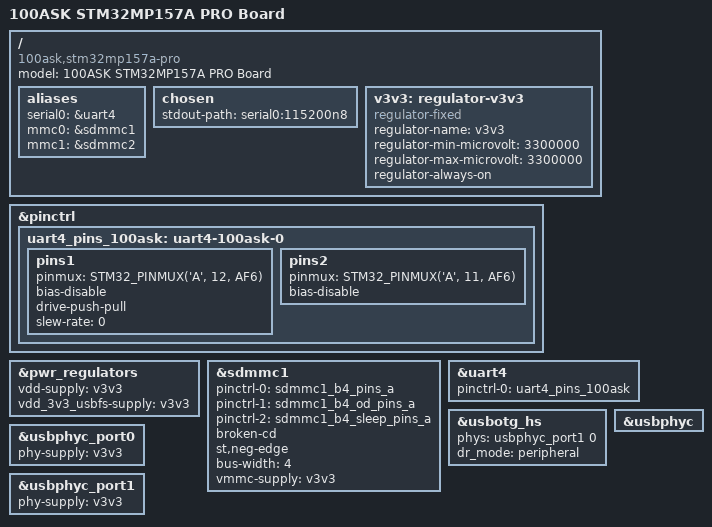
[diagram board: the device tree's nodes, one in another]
// SPDX-License-Identifier: (GPL-2.0+ OR BSD-3-Clause)
/*
 * 100ASK STM32MP157 PRO carrier board with a MYIR MYC-YA157C core board.
 */

/dts-v1/;

#include "stm32mp157a-myc-ya157c-som.dtsi"

/ {
	model = "100ASK STM32MP157A PRO Board";
	compatible = "100ask,stm32mp157a-pro", "myir,stm32mp157a-myc-ya157c", "st,stm32mp157";

	aliases {
		serial0 = &uart4;
		mmc0 = &sdmmc1;
		mmc1 = &sdmmc2;
	};

	chosen {
		stdout-path = "serial0:115200n8";
	};

	/* 3.3 V from the carrier's MP2143DJ, always on */
	v3v3: regulator-v3v3 {
		compatible = "regulator-fixed";
		regulator-name = "v3v3";
		regulator-min-microvolt = <3300000>;
		regulator-max-microvolt = <3300000>;
		regulator-always-on;
	};
};

&pinctrl {
	uart4_pins_100ask: uart4-100ask-0 {
		pins1 {
			pinmux = <STM32_PINMUX('A', 12, AF6)>; /* UART4_TX */
			bias-disable;
			drive-push-pull;
			slew-rate = <0>;
		};
		pins2 {
			pinmux = <STM32_PINMUX('A', 11, AF6)>; /* UART4_RX */
			bias-disable;
		};
	};
};

&pwr_regulators {
	vdd-supply = <&v3v3>;
	vdd_3v3_usbfs-supply = <&v3v3>;
};

/* microSD slot */
&sdmmc1 {
	pinctrl-names = "default", "opendrain", "sleep";
	pinctrl-0 = <&sdmmc1_b4_pins_a>;
	pinctrl-1 = <&sdmmc1_b4_od_pins_a>;
	pinctrl-2 = <&sdmmc1_b4_sleep_pins_a>;
	broken-cd;
	st,neg-edge;
	bus-width = <4>;
	vmmc-supply = <&v3v3>;
	status = "okay";
};

/* debug console, routed to the carrier's USB-serial bridge */
&uart4 {
	pinctrl-names = "default";
	pinctrl-0 = <&uart4_pins_100ask>;
	/delete-property/dmas;
	/delete-property/dma-names;
	status = "okay";
};

/* USB OTG (Type-C): STM32CubeProgrammer DFU / stm32prog */
&usbotg_hs {
	phys = <&usbphyc_port1 0>;
	phy-names = "usb2-phy";
	dr_mode = "peripheral";
	status = "okay";
};

&usbphyc {
	status = "okay";
};

&usbphyc_port0 {
	phy-supply = <&v3v3>;
};

&usbphyc_port1 {
	phy-supply = <&v3v3>;
};
